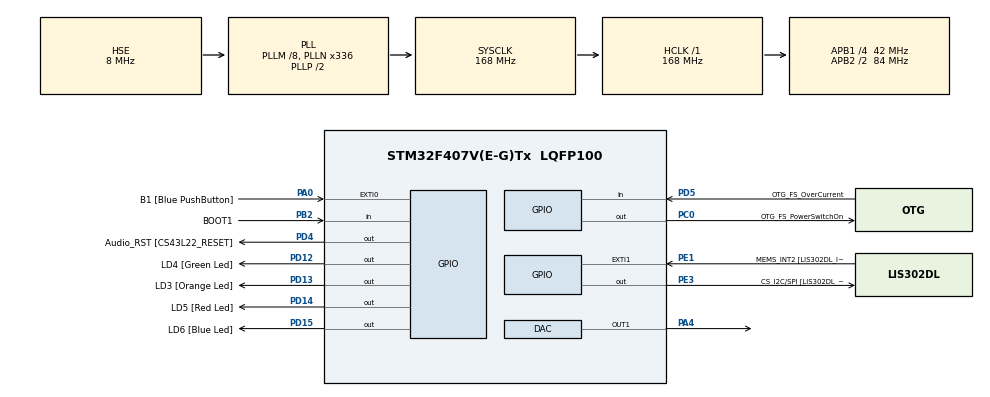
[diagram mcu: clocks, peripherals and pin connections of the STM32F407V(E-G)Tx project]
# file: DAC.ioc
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DAC.DAC_Trigger=DAC_TRIGGER_T6_TRGO
Dma.DAC1.0.Channel=DMA_CHANNEL_7
Dma.DAC1.0.Direction=DMA_MEMORY_TO_PERIPH
Dma.DAC1.0.FIFOMode=DMA_FIFOMODE_DISABLE
Dma.DAC1.0.Instance=DMA1_Stream5
Dma.DAC1.0.MemDataAlignment=DMA_MDATAALIGN_WORD
Dma.DAC1.0.MemInc=DMA_MINC_ENABLE
Dma.DAC1.0.Mode=DMA_CIRCULAR
Dma.DAC1.0.PeriphDataAlignment=DMA_PDATAALIGN_WORD
Dma.DAC1.0.PeriphInc=DMA_PINC_DISABLE
Dma.DAC1.0.Priority=DMA_PRIORITY_LOW
Dma.Request0=DAC1
Mcu.Family=STM32F4
Mcu.Name=STM32F407V(E-G)Tx
Mcu.Package=LQFP100
NVIC.DMA1_Stream5_IRQn=true\:0\:0\:false
NVIC.PriorityGroup=NVIC_PRIORITYGROUP_0
PA0-WKUP.GPIO_Label=B1 [Blue PushButton]
PA0-WKUP.GPIO_ModeDefaultEXTI=GPIO_MODE_EVT_RISING
PA0-WKUP.GPIO_PuPd=GPIO_NOPULL
PA0-WKUP.Signal=GPXTI0
PA13.GPIO_Label=SWDIO
PA13.Mode=Trace-Asynchronous_SW
PA13.Signal=SYS_JTMS-SWDIO
PA14.GPIO_Label=SWCLK
PA14.Mode=Trace-Asynchronous_SW
PA14.Signal=SYS_JTCK-SWCLK
PA4.Signal=COMP_DAC1_group
PB2.GPIO_Label=BOOT1
PB2.GPIO_Mode=GPIO_MODE_INPUT
PB2.GPIO_PuPd=GPIO_NOPULL
PB2.Signal=GPIO_Input
PB3.GPIO_Label=SWO
PB3.Mode=Trace-Asynchronous_SW
PB3.Signal=SYS_JTDO-SWO
PC0.GPIO_Label=OTG_FS_PowerSwitchOn
PC0.GPIO_PuPd=GPIO_NOPULL
PC0.GPIO_Speed=GPIO_SPEED_LOW
PC0.Signal=GPIO_Output
PD12.GPIO_Label=LD4 [Green Led]
PD12.GPIO_PuPd=GPIO_NOPULL
PD12.GPIO_Speed=GPIO_SPEED_LOW
PD12.Signal=GPIO_Output
PD13.GPIO_Label=LD3 [Orange Led]
PD13.GPIO_PuPd=GPIO_NOPULL
PD13.GPIO_Speed=GPIO_SPEED_LOW
PD13.Signal=GPIO_Output
PD14.GPIO_Label=LD5 [Red Led]
PD14.GPIO_PuPd=GPIO_NOPULL
PD14.GPIO_Speed=GPIO_SPEED_LOW
PD14.Signal=GPIO_Output
PD15.GPIO_Label=LD6 [Blue Led]
PD15.GPIO_PuPd=GPIO_NOPULL
PD15.GPIO_Speed=GPIO_SPEED_LOW
PD15.Signal=GPIO_Output
PD4.GPIO_Label=Audio_RST [CS43L22_RESET]
PD4.GPIO_PuPd=GPIO_NOPULL
PD4.GPIO_Speed=GPIO_SPEED_LOW
PD4.Signal=GPIO_Output
PD5.GPIO_Label=OTG_FS_OverCurrent
PD5.GPIO_Mode=GPIO_MODE_INPUT
PD5.GPIO_PuPd=GPIO_NOPULL
PD5.Signal=GPIO_Input
PE1.GPIO_Label=MEMS_INT2 [LIS302DL_INT2]
PE1.GPIO_ModeDefaultEXTI=GPIO_MODE_EVT_RISING
PE1.GPIO_PuPd=GPIO_NOPULL
PE1.Signal=GPXTI1
PE3.GPIO_Label=CS_I2C/SPI [LIS302DL_CS_I2C/SPI]
PE3.GPIO_PuPd=GPIO_NOPULL
PE3.GPIO_Speed=GPIO_SPEED_LOW
PE3.Signal=GPIO_Output
PH0-OSC_IN.GPIO_Label=PH0-OSC_IN
PH0-OSC_IN.Mode=HSE-External-Oscillator
PH0-OSC_IN.Signal=RCC_OSC_IN
PH1-OSC_OUT.GPIO_Label=PH1-OSC_OUT
PH1-OSC_OUT.Mode=HSE-External-Oscillator
PH1-OSC_OUT.Signal=RCC_OSC_OUT
ProjectManager.TargetToolchain=MDK-ARM V5
RCC.AHBFreq_Value=168000000
RCC.APB1CLKDivider=RCC_HCLK_DIV4
RCC.APB1Freq_Value=42000000
RCC.APB1TimFreq_Value=84000000
RCC.APB2CLKDivider=RCC_HCLK_DIV2
RCC.APB2Freq_Value=84000000
RCC.APB2TimFreq_Value=168000000
RCC.CortexFreq_Value=168000000
RCC.HCLKFreq_Value=168000000
RCC.HSE_VALUE=8000000
RCC.HSI_VALUE=16000000
RCC.LSE_VALUE=32768
RCC.PLLM=8
RCC.PLLN=336
RCC.PLLQ=7
RCC.PLLSourceVirtual=RCC_PLLSOURCE_HSE
RCC.SYSCLKFreq_VALUE=168000000
RCC.SYSCLKSource=RCC_SYSCLKSOURCE_PLLCLK
RCC.VCOOutputFreq_Value=336000000
SH.COMP_DAC1_group.0=DAC_OUT1,DAC_OUT1
TIM6.Period=656
TIM6.TIM_MasterOutputTrigger=TIM_TRGO_UPDATE
VP_TIM6_VS_ClockSourceINT.Mode=Enable_Timer
board=STM32F4DISCOVERY

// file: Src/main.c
/**
  ******************************************************************************
  * File Name          : main.c
  * Description        : Main program body
  ******************************************************************************
  *
  * COPYRIGHT(c) 2016 STMicroelectronics
  *
  * Redistribution and use in source and binary forms, with or without modification,
  * are permitted provided that the following conditions are met:
  *   1. Redistributions of source code must retain the above copyright notice,
  *      this list of conditions and the following disclaimer.
  *   2. Redistributions in binary form must reproduce the above copyright notice,
  *      this list of conditions and the following disclaimer in the documentation
  *      and/or other materials provided with the distribution.
  *   3. Neither the name of STMicroelectronics nor the names of its contributors
  *      may be used to endorse or promote products derived from this software
  *      without specific prior written permission.
  *
  * THIS SOFTWARE IS PROVIDED BY THE COPYRIGHT HOLDERS AND CONTRIBUTORS "AS IS"
  * AND ANY EXPRESS OR IMPLIED WARRANTIES, INCLUDING, BUT NOT LIMITED TO, THE
  * IMPLIED WARRANTIES OF MERCHANTABILITY AND FITNESS FOR A PARTICULAR PURPOSE ARE
  * DISCLAIMED. IN NO EVENT SHALL THE COPYRIGHT HOLDER OR CONTRIBUTORS BE LIABLE
  * FOR ANY DIRECT, INDIRECT, INCIDENTAL, SPECIAL, EXEMPLARY, OR CONSEQUENTIAL
  * DAMAGES (INCLUDING, BUT NOT LIMITED TO, PROCUREMENT OF SUBSTITUTE GOODS OR
  * SERVICES; LOSS OF USE, DATA, OR PROFITS; OR BUSINESS INTERRUPTION) HOWEVER
  * CAUSED AND ON ANY THEORY OF LIABILITY, WHETHER IN CONTRACT, STRICT LIABILITY,
  * OR TORT (INCLUDING NEGLIGENCE OR OTHERWISE) ARISING IN ANY WAY OUT OF THE USE
  * OF THIS SOFTWARE, EVEN IF ADVISED OF THE POSSIBILITY OF SUCH DAMAGE.
  *
  ******************************************************************************
  */
#include "stm32f4xx_hal.h"

DAC_HandleTypeDef hdac;
DMA_HandleTypeDef hdma_dac1;

TIM_HandleTypeDef htim6;

/* USER CODE BEGIN PV */
/* Private variables ---------------------------------------------------------*/
uint32_t sine_index=0;
/*
uint32_t SineWave[32]={2047, 1648, 1264, 910, 600,  345,
                    156, 39,  0,  39,  156,  345,
                    600, 910, 1264, 1648, 2048, 2447,
                    2831, 3185, 3495, 3750, 3939, 4056,
                    4095, 4056, 3939, 3750, 3495, 3185,
                    2831, 2447};
										*/

uint32_t SineWavePattern[64] = {2048, 2248, 2447, 2642, 2831, 3013, 3185,3346,3495,3630, 3750, 3853, 3939, 4007, 4056, 4085, 4095, 4085, 4056, 4007, 3939, 3853, 3750, 3630,3495, 3346, 3185, 3013, 2831, 2642, 2447, 2248, 2048, 1847, 1648, 1453, 1264, 1082, 910, 749, 600, 465, 345, 242, 156, 88, 39, 10, 0, 10, 39, 88, 156, 242, 345, 465, 600, 749, 910, 1082, 1264, 1453, 1648, 1847};
	/* USER CODE END PV */

void SystemClock_Config(void);
static void MX_GPIO_Init(void);
static void MX_DMA_Init(void);
static void MX_DAC_Init(void);
static void MX_TIM6_Init(void);

/* USER CODE BEGIN PFP */
/* Private function prototypes -----------------------------------------------*/
/* USER CODE END PFP */

int main(void)
{

  /* MCU Configuration----------------------------------------------------------*/

  /* Reset of all peripherals, Initializes the Flash interface and the Systick. */
  HAL_Init();

  /* Configure the system clock */
  SystemClock_Config();

  /* Initialize all configured peripherals */
  MX_GPIO_Init();
  MX_DMA_Init();
  MX_DAC_Init();
  MX_TIM6_Init();

  /* Infinite loop */
  /* USER CODE BEGIN WHILE */
	HAL_TIM_Base_Start(&htim6);
	HAL_DAC_Start(&hdac,DAC_CHANNEL_1);
	HAL_DAC_Start_DMA(&hdac,DAC_CHANNEL_1,(uint32_t *)&SineWavePattern,64,DAC_ALIGN_12B_R);
	while(1)
  {

  /* USER CODE END WHILE */

  }

}

/** System Clock Configuration
*/
void SystemClock_Config(void)
{

  RCC_OscInitTypeDef RCC_OscInitStruct;
  RCC_ClkInitTypeDef RCC_ClkInitStruct;

  __PWR_CLK_ENABLE();

  __HAL_PWR_VOLTAGESCALING_CONFIG(PWR_REGULATOR_VOLTAGE_SCALE1);

  RCC_OscInitStruct.OscillatorType = RCC_OSCILLATORTYPE_HSE;
  RCC_OscInitStruct.HSEState = RCC_HSE_ON;
  RCC_OscInitStruct.PLL.PLLState = RCC_PLL_ON;
  RCC_OscInitStruct.PLL.PLLSource = RCC_PLLSOURCE_HSE;
  RCC_OscInitStruct.PLL.PLLM = 8;
  RCC_OscInitStruct.PLL.PLLN = 336;
  RCC_OscInitStruct.PLL.PLLP = RCC_PLLP_DIV2;
  RCC_OscInitStruct.PLL.PLLQ = 7;
  HAL_RCC_OscConfig(&RCC_OscInitStruct);

  RCC_ClkInitStruct.ClockType = RCC_CLOCKTYPE_SYSCLK|RCC_CLOCKTYPE_PCLK1
                              |RCC_CLOCKTYPE_PCLK2;
  RCC_ClkInitStruct.SYSCLKSource = RCC_SYSCLKSOURCE_PLLCLK;
  RCC_ClkInitStruct.AHBCLKDivider = RCC_SYSCLK_DIV1;
  RCC_ClkInitStruct.APB1CLKDivider = RCC_HCLK_DIV4;
  RCC_ClkInitStruct.APB2CLKDivider = RCC_HCLK_DIV2;
  HAL_RCC_ClockConfig(&RCC_ClkInitStruct, FLASH_LATENCY_5);

  HAL_SYSTICK_Config(HAL_RCC_GetHCLKFreq()/1000);

  HAL_SYSTICK_CLKSourceConfig(SYSTICK_CLKSOURCE_HCLK);

  /* SysTick_IRQn interrupt configuration */
  HAL_NVIC_SetPriority(SysTick_IRQn, 0, 0);
}

/* DAC init function */
void MX_DAC_Init(void)
{

  DAC_ChannelConfTypeDef sConfig;

    /**DAC Initialization
    */
  hdac.Instance = DAC;
  HAL_DAC_Init(&hdac);

    /**DAC channel OUT1 config
    */
  sConfig.DAC_Trigger = DAC_TRIGGER_T6_TRGO;
  sConfig.DAC_OutputBuffer = DAC_OUTPUTBUFFER_ENABLE;
  HAL_DAC_ConfigChannel(&hdac, &sConfig, DAC_CHANNEL_1);

}

/* TIM6 init function */
void MX_TIM6_Init(void)
{

  TIM_MasterConfigTypeDef sMasterConfig;

  htim6.Instance = TIM6;
  htim6.Init.Prescaler = 0;
  htim6.Init.CounterMode = TIM_COUNTERMODE_UP;
  htim6.Init.Period = 500;
  HAL_TIM_Base_Init(&htim6);

  sMasterConfig.MasterOutputTrigger = TIM_TRGO_UPDATE;
  sMasterConfig.MasterSlaveMode = TIM_MASTERSLAVEMODE_DISABLE;
  HAL_TIMEx_MasterConfigSynchronization(&htim6, &sMasterConfig);

}

void MX_DMA_Init(void)
{
  /* DMA controller clock enable */
  __DMA1_CLK_ENABLE();

  /* DMA interrupt init */
  HAL_NVIC_SetPriority(DMA1_Stream5_IRQn, 0, 0);
  HAL_NVIC_EnableIRQ(DMA1_Stream5_IRQn);

}

/** Configure pins as
        * Analog
        * Input
        * Output
        * EVENT_OUT
        * EXTI
*/
void MX_GPIO_Init(void)
{

  GPIO_InitTypeDef GPIO_InitStruct;

  /* GPIO Ports Clock Enable */
  __GPIOE_CLK_ENABLE();
  __GPIOH_CLK_ENABLE();
  __GPIOC_CLK_ENABLE();
  __GPIOA_CLK_ENABLE();
  __GPIOB_CLK_ENABLE();
  __GPIOD_CLK_ENABLE();

  /*Configure GPIO pin : CS_I2C_SPI_Pin */
  GPIO_InitStruct.Pin = CS_I2C_SPI_Pin;
  GPIO_InitStruct.Mode = GPIO_MODE_OUTPUT_PP;
  GPIO_InitStruct.Pull = GPIO_NOPULL;
  GPIO_InitStruct.Speed = GPIO_SPEED_LOW;
  HAL_GPIO_Init(CS_I2C_SPI_GPIO_Port, &GPIO_InitStruct);

  /*Configure GPIO pin : OTG_FS_PowerSwitchOn_Pin */
  GPIO_InitStruct.Pin = OTG_FS_PowerSwitchOn_Pin;
  GPIO_InitStruct.Mode = GPIO_MODE_OUTPUT_PP;
  GPIO_InitStruct.Pull = GPIO_NOPULL;
  GPIO_InitStruct.Speed = GPIO_SPEED_LOW;
  HAL_GPIO_Init(OTG_FS_PowerSwitchOn_GPIO_Port, &GPIO_InitStruct);

  /*Configure GPIO pin : B1_Pin */
  GPIO_InitStruct.Pin = B1_Pin;
  GPIO_InitStruct.Mode = GPIO_MODE_EVT_RISING;
  GPIO_InitStruct.Pull = GPIO_NOPULL;
  HAL_GPIO_Init(B1_GPIO_Port, &GPIO_InitStruct);

  /*Configure GPIO pin : BOOT1_Pin */
  GPIO_InitStruct.Pin = BOOT1_Pin;
  GPIO_InitStruct.Mode = GPIO_MODE_INPUT;
  GPIO_InitStruct.Pull = GPIO_NOPULL;
  HAL_GPIO_Init(BOOT1_GPIO_Port, &GPIO_InitStruct);

  /*Configure GPIO pins : LD4_Pin LD3_Pin LD5_Pin LD6_Pin
                           Audio_RST_Pin */
  GPIO_InitStruct.Pin = LD4_Pin|LD3_Pin|LD5_Pin|LD6_Pin
                          |Audio_RST_Pin;
  GPIO_InitStruct.Mode = GPIO_MODE_OUTPUT_PP;
  GPIO_InitStruct.Pull = GPIO_NOPULL;
  GPIO_InitStruct.Speed = GPIO_SPEED_LOW;
  HAL_GPIO_Init(GPIOD, &GPIO_InitStruct);

  /*Configure GPIO pin : OTG_FS_OverCurrent_Pin */
  GPIO_InitStruct.Pin = OTG_FS_OverCurrent_Pin;
  GPIO_InitStruct.Mode = GPIO_MODE_INPUT;
  GPIO_InitStruct.Pull = GPIO_NOPULL;
  HAL_GPIO_Init(OTG_FS_OverCurrent_GPIO_Port, &GPIO_InitStruct);

  /*Configure GPIO pin : MEMS_INT2_Pin */
  GPIO_InitStruct.Pin = MEMS_INT2_Pin;
  GPIO_InitStruct.Mode = GPIO_MODE_EVT_RISING;
  GPIO_InitStruct.Pull = GPIO_NOPULL;
  HAL_GPIO_Init(MEMS_INT2_GPIO_Port, &GPIO_InitStruct);

}

/************************ (C) COPYRIGHT STMicroelectronics *****END OF FILE****/
